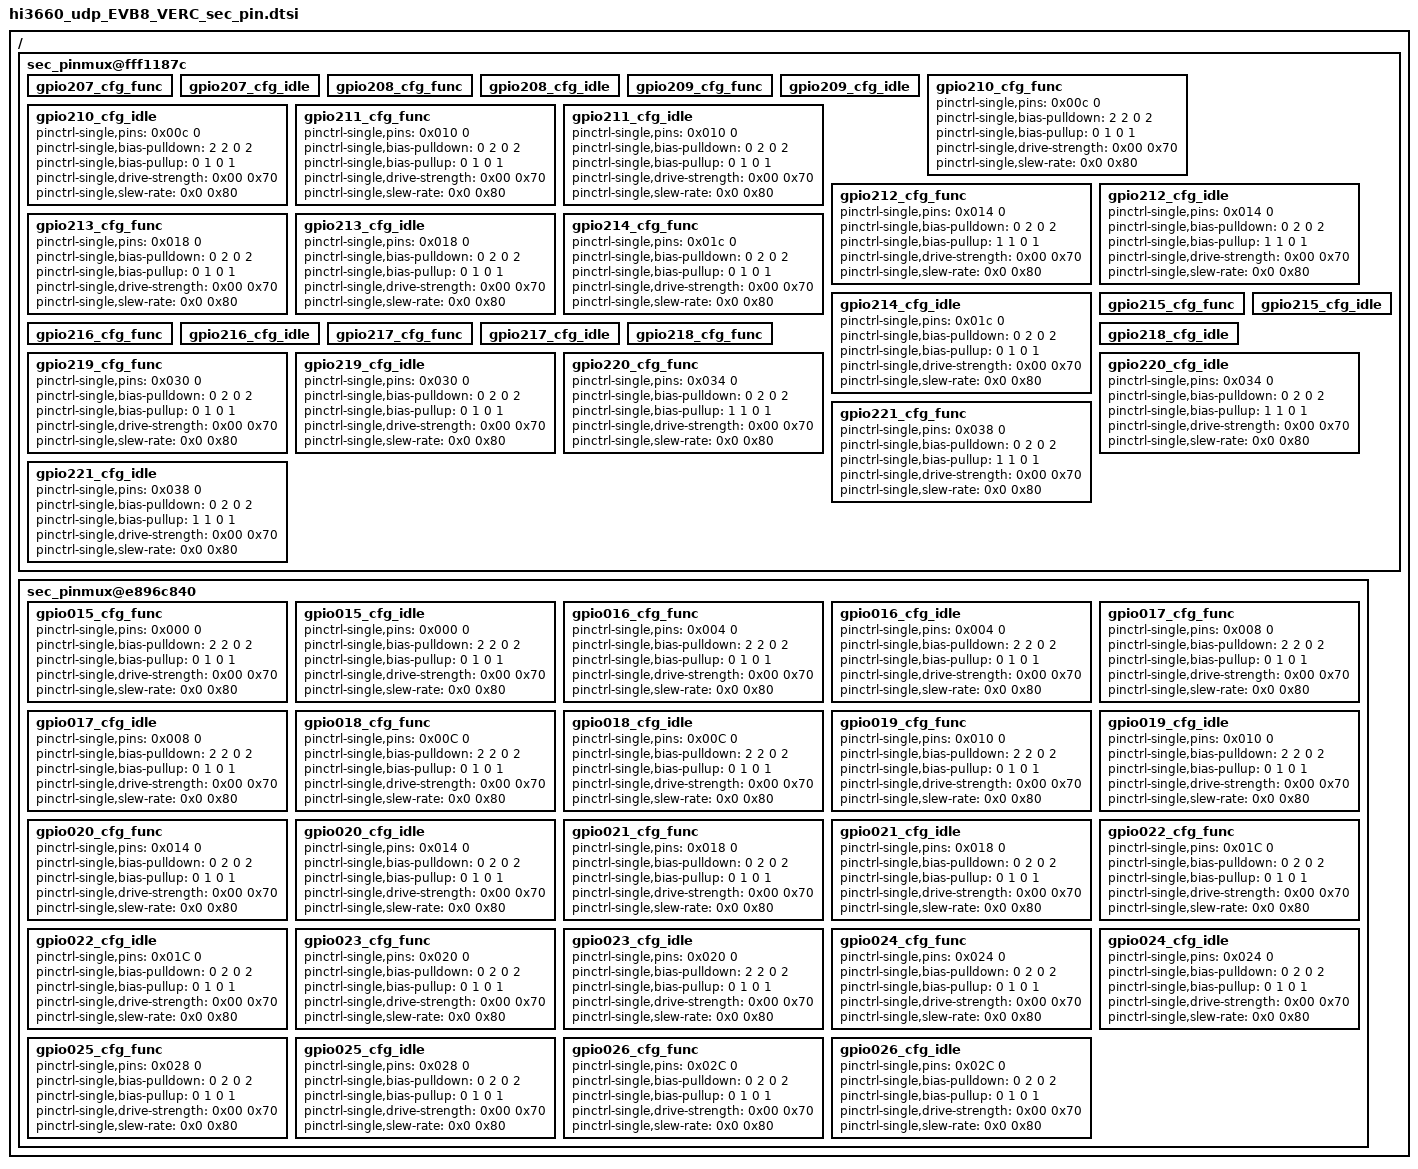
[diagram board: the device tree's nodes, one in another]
/ {
    sec_pinmux@fff1187c {
		gpio207_cfg_func: gpio207_cfg_func {
		};
		gpio207_cfg_idle: gpio207_cfg_idle {
		};

		gpio208_cfg_func: gpio208_cfg_func {
		};
		gpio208_cfg_idle: gpio208_cfg_idle {
		};

		gpio209_cfg_func: gpio209_cfg_func {
		};
		gpio209_cfg_idle: gpio209_cfg_idle {
		};

		gpio210_cfg_func: gpio210_cfg_func {
                     pinctrl-single,pins = <0x00c  0>;
                     pinctrl-single,bias-pulldown = <2 2 0 2>;
                     pinctrl-single,bias-pullup = <0 1 0 1>;
                     pinctrl-single,drive-strength = <0x00 0x70>;
                     pinctrl-single,slew-rate = <0x0 0x80>;
		};
		gpio210_cfg_idle: gpio210_cfg_idle {
                     pinctrl-single,pins = <0x00c  0>;
                     pinctrl-single,bias-pulldown = <2 2 0 2>;
                     pinctrl-single,bias-pullup = <0 1 0 1>;
                     pinctrl-single,drive-strength = <0x00 0x70>;
                     pinctrl-single,slew-rate = <0x0 0x80>;
		};

		gpio211_cfg_func: gpio211_cfg_func {
                     pinctrl-single,pins = <0x010  0>;
                     pinctrl-single,bias-pulldown = <0 2 0 2>;
                     pinctrl-single,bias-pullup = <0 1 0 1>;
                     pinctrl-single,drive-strength = <0x00 0x70>;
                     pinctrl-single,slew-rate = <0x0 0x80>;
		};
		gpio211_cfg_idle: gpio211_cfg_idle {
                     pinctrl-single,pins = <0x010  0>;
                     pinctrl-single,bias-pulldown = <0 2 0 2>;
                     pinctrl-single,bias-pullup = <0 1 0 1>;
                     pinctrl-single,drive-strength = <0x00 0x70>;
                     pinctrl-single,slew-rate = <0x0 0x80>;
		};

		gpio212_cfg_func: gpio212_cfg_func {
                     pinctrl-single,pins = <0x014  0>;
                     pinctrl-single,bias-pulldown = <0 2 0 2>;
                     pinctrl-single,bias-pullup = <1 1 0 1>;
                     pinctrl-single,drive-strength = <0x00 0x70>;
                     pinctrl-single,slew-rate = <0x0 0x80>;
		};
		gpio212_cfg_idle: gpio212_cfg_idle {
                     pinctrl-single,pins = <0x014  0>;
                     pinctrl-single,bias-pulldown = <0 2 0 2>;
                     pinctrl-single,bias-pullup = <1 1 0 1>;
                     pinctrl-single,drive-strength = <0x00 0x70>;
                     pinctrl-single,slew-rate = <0x0 0x80>;
		};

		gpio213_cfg_func: gpio213_cfg_func {
                     pinctrl-single,pins = <0x018  0>;
                     pinctrl-single,bias-pulldown = <0 2 0 2>;
                     pinctrl-single,bias-pullup = <0 1 0 1>;
                     pinctrl-single,drive-strength = <0x00 0x70>;
                     pinctrl-single,slew-rate = <0x0 0x80>;
		};
		gpio213_cfg_idle: gpio213_cfg_idle {
                     pinctrl-single,pins = <0x018  0>;
                     pinctrl-single,bias-pulldown = <0 2 0 2>;
                     pinctrl-single,bias-pullup = <0 1 0 1>;
                     pinctrl-single,drive-strength = <0x00 0x70>;
                     pinctrl-single,slew-rate = <0x0 0x80>;
		};

		gpio214_cfg_func: gpio214_cfg_func {
                     pinctrl-single,pins = <0x01c  0>;
                     pinctrl-single,bias-pulldown = <0 2 0 2>;
                     pinctrl-single,bias-pullup = <0 1 0 1>;
                     pinctrl-single,drive-strength = <0x00 0x70>;
                     pinctrl-single,slew-rate = <0x0 0x80>;
		};
		gpio214_cfg_idle: gpio214_cfg_idle {
                     pinctrl-single,pins = <0x01c  0>;
                     pinctrl-single,bias-pulldown = <0 2 0 2>;
                     pinctrl-single,bias-pullup = <0 1 0 1>;
                     pinctrl-single,drive-strength = <0x00 0x70>;
                     pinctrl-single,slew-rate = <0x0 0x80>;
		};

		gpio215_cfg_func: gpio215_cfg_func {
		};
		gpio215_cfg_idle: gpio215_cfg_idle {
		};

		gpio216_cfg_func: gpio216_cfg_func {
		};
		gpio216_cfg_idle: gpio216_cfg_idle {
		};

		gpio217_cfg_func: gpio217_cfg_func {
		};
		gpio217_cfg_idle: gpio217_cfg_idle {
		};

		gpio218_cfg_func: gpio218_cfg_func {
		};
		gpio218_cfg_idle: gpio218_cfg_idle {
		};

		gpio219_cfg_func: gpio219_cfg_func {
                     pinctrl-single,pins = <0x030  0>;
                     pinctrl-single,bias-pulldown = <0 2 0 2>;
                     pinctrl-single,bias-pullup = <0 1 0 1>;
                     pinctrl-single,drive-strength = <0x00 0x70>;
                     pinctrl-single,slew-rate = <0x0 0x80>;
		};
		gpio219_cfg_idle: gpio219_cfg_idle {
                     pinctrl-single,pins = <0x030  0>;
                     pinctrl-single,bias-pulldown = <0 2 0 2>;
                     pinctrl-single,bias-pullup = <0 1 0 1>;
                     pinctrl-single,drive-strength = <0x00 0x70>;
                     pinctrl-single,slew-rate = <0x0 0x80>;
		};

		gpio220_cfg_func: gpio220_cfg_func {
                     pinctrl-single,pins = <0x034  0>;
                     pinctrl-single,bias-pulldown = <0 2 0 2>;
                     pinctrl-single,bias-pullup = <1 1 0 1>;
                     pinctrl-single,drive-strength = <0x00 0x70>;
                     pinctrl-single,slew-rate = <0x0 0x80>;
		};
		gpio220_cfg_idle: gpio220_cfg_idle {
                     pinctrl-single,pins = <0x034  0>;
                     pinctrl-single,bias-pulldown = <0 2 0 2>;
                     pinctrl-single,bias-pullup = <1 1 0 1>;
                     pinctrl-single,drive-strength = <0x00 0x70>;
                     pinctrl-single,slew-rate = <0x0 0x80>;
		};

		gpio221_cfg_func: gpio221_cfg_func {
                     pinctrl-single,pins = <0x038  0>;
                     pinctrl-single,bias-pulldown = <0 2 0 2>;
                     pinctrl-single,bias-pullup = <1 1 0 1>;
                     pinctrl-single,drive-strength = <0x00 0x70>;
                     pinctrl-single,slew-rate = <0x0 0x80>;
		};
		gpio221_cfg_idle: gpio221_cfg_idle {
                     pinctrl-single,pins = <0x038  0>;
                     pinctrl-single,bias-pulldown = <0 2 0 2>;
                     pinctrl-single,bias-pullup = <1 1 0 1>;
                     pinctrl-single,drive-strength = <0x00 0x70>;
                     pinctrl-single,slew-rate = <0x0 0x80>;
		};

    };

    sec_pinmux@e896c840 {
		gpio015_cfg_func: gpio015_cfg_func {
                     pinctrl-single,pins = <0x000  0>;
                     pinctrl-single,bias-pulldown = <2 2 0 2>;
                     pinctrl-single,bias-pullup = <0 1 0 1>;
                     pinctrl-single,drive-strength = <0x00 0x70>;
                     pinctrl-single,slew-rate = <0x0 0x80>;
		};
		gpio015_cfg_idle: gpio015_cfg_idle {
                     pinctrl-single,pins = <0x000  0>;
                     pinctrl-single,bias-pulldown = <2 2 0 2>;
                     pinctrl-single,bias-pullup = <0 1 0 1>;
                     pinctrl-single,drive-strength = <0x00 0x70>;
                     pinctrl-single,slew-rate = <0x0 0x80>;
		};

		gpio016_cfg_func: gpio016_cfg_func {
                     pinctrl-single,pins = <0x004  0>;
                     pinctrl-single,bias-pulldown = <2 2 0 2>;
                     pinctrl-single,bias-pullup = <0 1 0 1>;
                     pinctrl-single,drive-strength = <0x00 0x70>;
                     pinctrl-single,slew-rate = <0x0 0x80>;
		};
		gpio016_cfg_idle: gpio016_cfg_idle {
                     pinctrl-single,pins = <0x004  0>;
                     pinctrl-single,bias-pulldown = <2 2 0 2>;
                     pinctrl-single,bias-pullup = <0 1 0 1>;
                     pinctrl-single,drive-strength = <0x00 0x70>;
                     pinctrl-single,slew-rate = <0x0 0x80>;
		};

		gpio017_cfg_func: gpio017_cfg_func {
                     pinctrl-single,pins = <0x008  0>;
                     pinctrl-single,bias-pulldown = <2 2 0 2>;
                     pinctrl-single,bias-pullup = <0 1 0 1>;
                     pinctrl-single,drive-strength = <0x00 0x70>;
                     pinctrl-single,slew-rate = <0x0 0x80>;
		};
		gpio017_cfg_idle: gpio017_cfg_idle {
                     pinctrl-single,pins = <0x008  0>;
                     pinctrl-single,bias-pulldown = <2 2 0 2>;
                     pinctrl-single,bias-pullup = <0 1 0 1>;
                     pinctrl-single,drive-strength = <0x00 0x70>;
                     pinctrl-single,slew-rate = <0x0 0x80>;
		};

		gpio018_cfg_func: gpio018_cfg_func {
                     pinctrl-single,pins = <0x00C  0>;
                     pinctrl-single,bias-pulldown = <2 2 0 2>;
                     pinctrl-single,bias-pullup = <0 1 0 1>;
                     pinctrl-single,drive-strength = <0x00 0x70>;
                     pinctrl-single,slew-rate = <0x0 0x80>;
		};
		gpio018_cfg_idle: gpio018_cfg_idle {
                     pinctrl-single,pins = <0x00C  0>;
                     pinctrl-single,bias-pulldown = <2 2 0 2>;
                     pinctrl-single,bias-pullup = <0 1 0 1>;
                     pinctrl-single,drive-strength = <0x00 0x70>;
                     pinctrl-single,slew-rate = <0x0 0x80>;
		};

		gpio019_cfg_func: gpio019_cfg_func {
                     pinctrl-single,pins = <0x010  0>;
                     pinctrl-single,bias-pulldown = <2 2 0 2>;
                     pinctrl-single,bias-pullup = <0 1 0 1>;
                     pinctrl-single,drive-strength = <0x00 0x70>;
                     pinctrl-single,slew-rate = <0x0 0x80>;
		};
		gpio019_cfg_idle: gpio019_cfg_idle {
                     pinctrl-single,pins = <0x010  0>;
                     pinctrl-single,bias-pulldown = <2 2 0 2>;
                     pinctrl-single,bias-pullup = <0 1 0 1>;
                     pinctrl-single,drive-strength = <0x00 0x70>;
                     pinctrl-single,slew-rate = <0x0 0x80>;
		};

		gpio020_cfg_func: gpio020_cfg_func {
                     pinctrl-single,pins = <0x014  0>;
                     pinctrl-single,bias-pulldown = <0 2 0 2>;
                     pinctrl-single,bias-pullup = <0 1 0 1>;
                     pinctrl-single,drive-strength = <0x00 0x70>;
                     pinctrl-single,slew-rate = <0x0 0x80>;
		};
		gpio020_cfg_idle: gpio020_cfg_idle {
                     pinctrl-single,pins = <0x014  0>;
                     pinctrl-single,bias-pulldown = <0 2 0 2>;
                     pinctrl-single,bias-pullup = <0 1 0 1>;
                     pinctrl-single,drive-strength = <0x00 0x70>;
                     pinctrl-single,slew-rate = <0x0 0x80>;
		};

		gpio021_cfg_func: gpio021_cfg_func {
                     pinctrl-single,pins = <0x018  0>;
                     pinctrl-single,bias-pulldown = <0 2 0 2>;
                     pinctrl-single,bias-pullup = <0 1 0 1>;
                     pinctrl-single,drive-strength = <0x00 0x70>;
                     pinctrl-single,slew-rate = <0x0 0x80>;
		};
		gpio021_cfg_idle: gpio021_cfg_idle {
                     pinctrl-single,pins = <0x018  0>;
                     pinctrl-single,bias-pulldown = <0 2 0 2>;
                     pinctrl-single,bias-pullup = <0 1 0 1>;
                     pinctrl-single,drive-strength = <0x00 0x70>;
                     pinctrl-single,slew-rate = <0x0 0x80>;
		};

		gpio022_cfg_func: gpio022_cfg_func {
                     pinctrl-single,pins = <0x01C  0>;
                     pinctrl-single,bias-pulldown = <0 2 0 2>;
                     pinctrl-single,bias-pullup = <0 1 0 1>;
                     pinctrl-single,drive-strength = <0x00 0x70>;
                     pinctrl-single,slew-rate = <0x0 0x80>;
		};
		gpio022_cfg_idle: gpio022_cfg_idle {
                     pinctrl-single,pins = <0x01C  0>;
                     pinctrl-single,bias-pulldown = <0 2 0 2>;
                     pinctrl-single,bias-pullup = <0 1 0 1>;
                     pinctrl-single,drive-strength = <0x00 0x70>;
                     pinctrl-single,slew-rate = <0x0 0x80>;
		};

		gpio023_cfg_func: gpio023_cfg_func {
                     pinctrl-single,pins = <0x020  0>;
                     pinctrl-single,bias-pulldown = <0 2 0 2>;
                     pinctrl-single,bias-pullup = <0 1 0 1>;
                     pinctrl-single,drive-strength = <0x00 0x70>;
                     pinctrl-single,slew-rate = <0x0 0x80>;
		};
		gpio023_cfg_idle: gpio023_cfg_idle {
                     pinctrl-single,pins = <0x020  0>;
                     pinctrl-single,bias-pulldown = <2 2 0 2>;
                     pinctrl-single,bias-pullup = <0 1 0 1>;
                     pinctrl-single,drive-strength = <0x00 0x70>;
                     pinctrl-single,slew-rate = <0x0 0x80>;
		};

		gpio024_cfg_func: gpio024_cfg_func {
                     pinctrl-single,pins = <0x024  0>;
                     pinctrl-single,bias-pulldown = <0 2 0 2>;
                     pinctrl-single,bias-pullup = <0 1 0 1>;
                     pinctrl-single,drive-strength = <0x00 0x70>;
                     pinctrl-single,slew-rate = <0x0 0x80>;
		};
		gpio024_cfg_idle: gpio024_cfg_idle {
                     pinctrl-single,pins = <0x024  0>;
                     pinctrl-single,bias-pulldown = <0 2 0 2>;
                     pinctrl-single,bias-pullup = <0 1 0 1>;
                     pinctrl-single,drive-strength = <0x00 0x70>;
                     pinctrl-single,slew-rate = <0x0 0x80>;
		};

		gpio025_cfg_func: gpio025_cfg_func {
                     pinctrl-single,pins = <0x028  0>;
                     pinctrl-single,bias-pulldown = <0 2 0 2>;
                     pinctrl-single,bias-pullup = <0 1 0 1>;
                     pinctrl-single,drive-strength = <0x00 0x70>;
                     pinctrl-single,slew-rate = <0x0 0x80>;
		};
		gpio025_cfg_idle: gpio025_cfg_idle {
                     pinctrl-single,pins = <0x028  0>;
                     pinctrl-single,bias-pulldown = <0 2 0 2>;
                     pinctrl-single,bias-pullup = <0 1 0 1>;
                     pinctrl-single,drive-strength = <0x00 0x70>;
                     pinctrl-single,slew-rate = <0x0 0x80>;
		};

		gpio026_cfg_func: gpio026_cfg_func {
                     pinctrl-single,pins = <0x02C  0>;
                     pinctrl-single,bias-pulldown = <0 2 0 2>;
                     pinctrl-single,bias-pullup = <0 1 0 1>;
                     pinctrl-single,drive-strength = <0x00 0x70>;
                     pinctrl-single,slew-rate = <0x0 0x80>;
		};
		gpio026_cfg_idle: gpio026_cfg_idle {
                     pinctrl-single,pins = <0x02C  0>;
                     pinctrl-single,bias-pulldown = <0 2 0 2>;
                     pinctrl-single,bias-pullup = <0 1 0 1>;
                     pinctrl-single,drive-strength = <0x00 0x70>;
                     pinctrl-single,slew-rate = <0x0 0x80>;
		};

    };

};
